# iospear310 register map
Registers are 32-bit, access not given, no defined reset value unless marked. A register's access mark holds for its fields unless they carry their own. Addresses are absolute; registers are grouped by the start of their names; [hi:lo] are bit positions; {n}, {i} and the like mark numbered series.

## MEMCTL
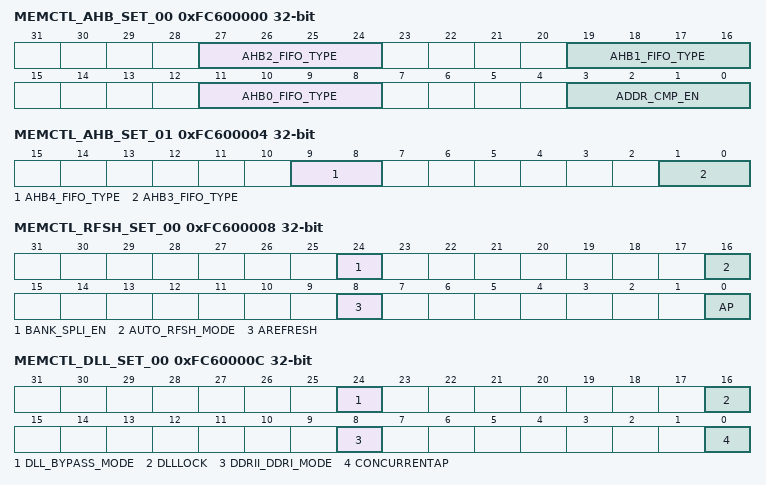
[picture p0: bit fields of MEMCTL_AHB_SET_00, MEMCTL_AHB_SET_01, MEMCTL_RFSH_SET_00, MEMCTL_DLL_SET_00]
0xFC600000 MEMCTL_AHB_SET_00
  [27:24] AHB2_FIFO_TYPE, [19:16] AHB1_FIFO_TYPE, [11:8] AHB0_FIFO_TYPE, [3:0] ADDR_CMP_EN
0xFC600004 MEMCTL_AHB_SET_01
  [9:8] AHB4_FIFO_TYPE, [1:0] AHB3_FIFO_TYPE
0xFC600008 MEMCTL_RFSH_SET_00
  [24] BANK_SPLI_EN, [16] AUTO_RFSH_MODE, [8] AREFRESH, [0] AP
0xFC60000C MEMCTL_DLL_SET_00
  [24] DLL_BYPASS_MODE, [16] DLLLOCK, [8] DDRII_DDRI_MODE, [0] CONCURRENTAP
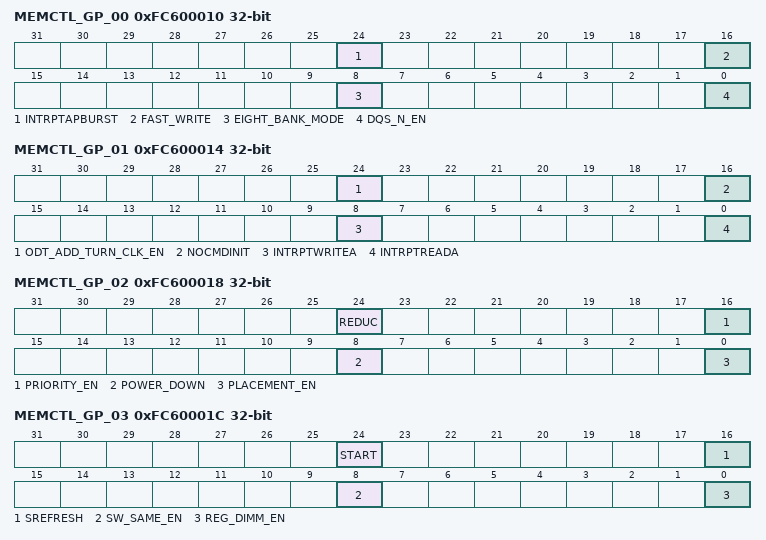
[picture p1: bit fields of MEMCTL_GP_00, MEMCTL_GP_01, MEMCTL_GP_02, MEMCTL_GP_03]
0xFC600010 MEMCTL_GP_00
  [24] INTRPTAPBURST, [16] FAST_WRITE, [8] EIGHT_BANK_MODE, [0] DQS_N_EN
0xFC600014 MEMCTL_GP_01
  [24] ODT_ADD_TURN_CLK_EN, [16] NOCMDINIT, [8] INTRPTWRITEA, [0] INTRPTREADA
0xFC600018 MEMCTL_GP_02
  [24] REDUC, [16] PRIORITY_EN, [8] POWER_DOWN, [0] PLACEMENT_EN
0xFC60001C MEMCTL_GP_03
  [24] START, [16] SREFRESH, [8] SW_SAME_EN, [0] REG_DIMM_EN
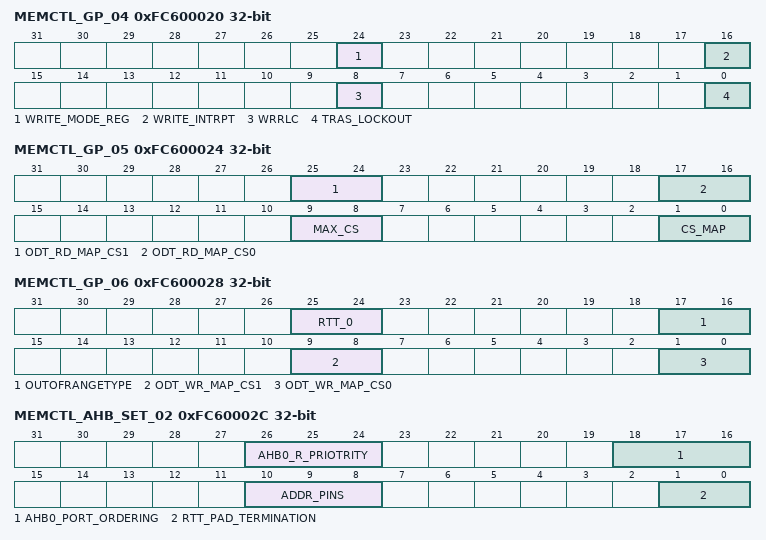
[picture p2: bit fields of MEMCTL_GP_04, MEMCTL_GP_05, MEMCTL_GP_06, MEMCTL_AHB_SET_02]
0xFC600020 MEMCTL_GP_04
  [24] WRITE_MODE_REG, [16] WRITE_INTRPT, [8] WRRLC, [0] TRAS_LOCKOUT
0xFC600024 MEMCTL_GP_05
  [25:24] ODT_RD_MAP_CS1, [17:16] ODT_RD_MAP_CS0, [9:8] MAX_CS, [1:0] CS_MAP
0xFC600028 MEMCTL_GP_06
  [25:24] RTT_0, [17:16] OUTOFRANGETYPE, [9:8] ODT_WR_MAP_CS1, [1:0] ODT_WR_MAP_CS0
0xFC60002C MEMCTL_AHB_SET_02
  [26:24] AHB0_R_PRIOTRITY, [18:16] AHB0_PORT_ORDERING, [10:8] ADDR_PINS, [1:0] RTT_PAD_TERMINATION
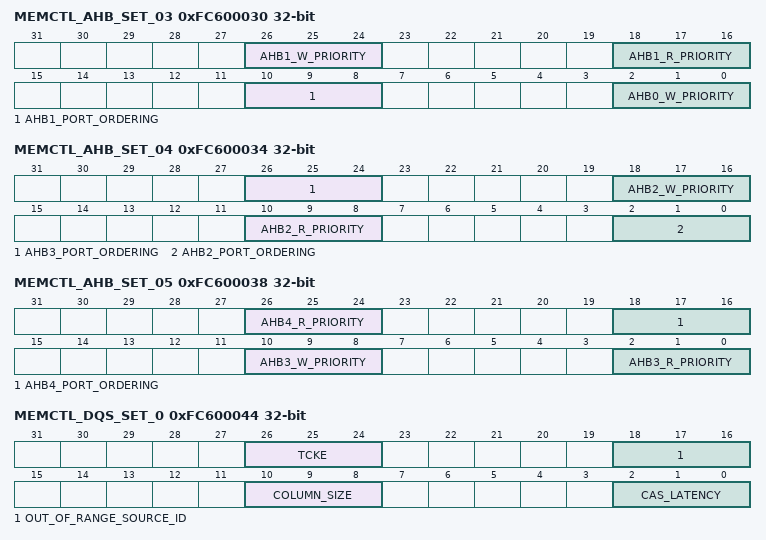
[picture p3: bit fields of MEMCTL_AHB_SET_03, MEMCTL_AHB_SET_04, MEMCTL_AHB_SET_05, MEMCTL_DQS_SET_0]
0xFC600030 MEMCTL_AHB_SET_03
  [26:24] AHB1_W_PRIORITY, [18:16] AHB1_R_PRIORITY, [10:8] AHB1_PORT_ORDERING, [2:0] AHB0_W_PRIORITY
0xFC600034 MEMCTL_AHB_SET_04
  [26:24] AHB3_PORT_ORDERING, [18:16] AHB2_W_PRIORITY, [10:8] AHB2_R_PRIORITY, [2:0] AHB2_PORT_ORDERING
0xFC600038 MEMCTL_AHB_SET_05
  [26:24] AHB4_R_PRIORITY, [18:16] AHB4_PORT_ORDERING, [10:8] AHB3_W_PRIORITY, [2:0] AHB3_R_PRIORITY
0xFC60003C MEMCTL_AHB_SET_06
  [2:0] AHB4_W_PRIORITY
0xFC600044 MEMCTL_DQS_SET_0
  [26:24] TCKE, [18:16] OUT_OF_RANGE_SOURCE_ID, [10:8] COLUMN_SIZE, [2:0] CAS_LATENCY
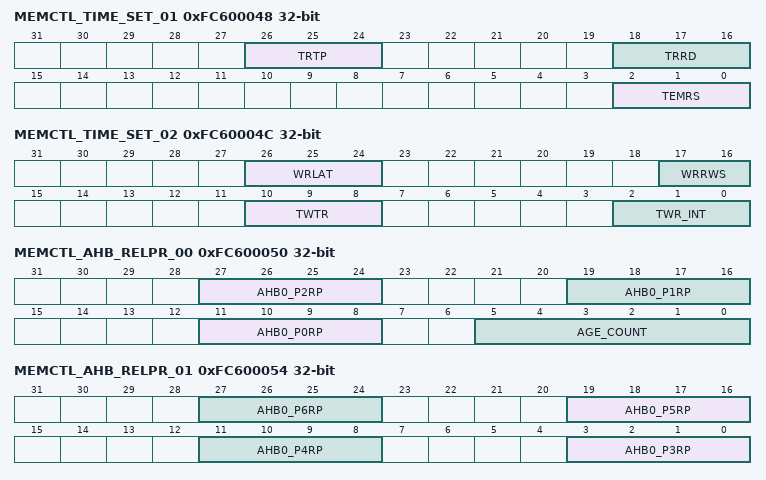
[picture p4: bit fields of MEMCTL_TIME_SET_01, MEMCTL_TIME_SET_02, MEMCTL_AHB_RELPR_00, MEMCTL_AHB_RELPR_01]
0xFC600048 MEMCTL_TIME_SET_01
  [26:24] TRTP, [18:16] TRRD, [2:0] TEMRS
0xFC60004C MEMCTL_TIME_SET_02
  [26:24] WRLAT, [17:16] WRRWS, [10:8] TWTR, [2:0] TWR_INT
0xFC600050 MEMCTL_AHB_RELPR_00
  [27:24] AHB0_P2RP, [19:16] AHB0_P1RP, [11:8] AHB0_P0RP, [5:0] AGE_COUNT
0xFC600054 MEMCTL_AHB_RELPR_01
  [8n-21:8n-24] AHB0_P{n}RP (n=3..6)
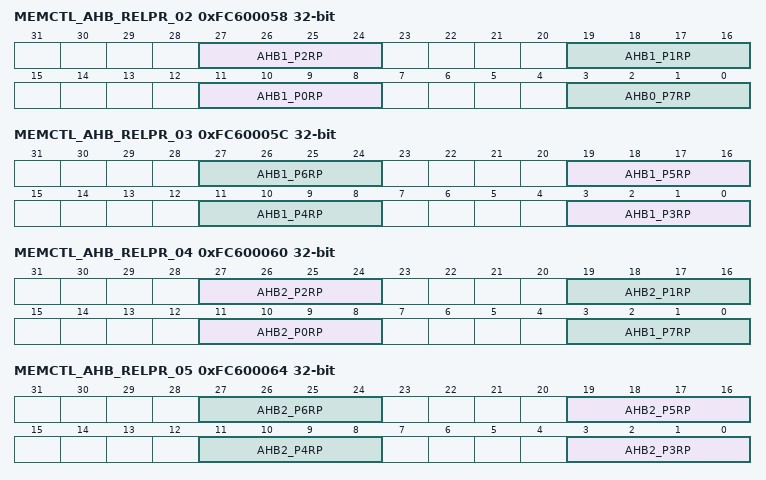
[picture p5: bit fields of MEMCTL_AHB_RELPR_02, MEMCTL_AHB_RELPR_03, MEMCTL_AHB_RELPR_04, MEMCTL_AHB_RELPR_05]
0xFC600058 MEMCTL_AHB_RELPR_02
  [27:24] AHB1_P2RP, [19:16] AHB1_P1RP, [11:8] AHB1_P0RP, [3:0] AHB0_P7RP
0xFC60005C MEMCTL_AHB_RELPR_03
  [8n-21:8n-24] AHB1_P{n}RP (n=3..6)
0xFC600060 MEMCTL_AHB_RELPR_04
  [27:24] AHB2_P2RP, [19:16] AHB2_P1RP, [11:8] AHB2_P0RP, [3:0] AHB1_P7RP
0xFC600064 MEMCTL_AHB_RELPR_05
  [8n-21:8n-24] AHB2_P{n}RP (n=3..6)
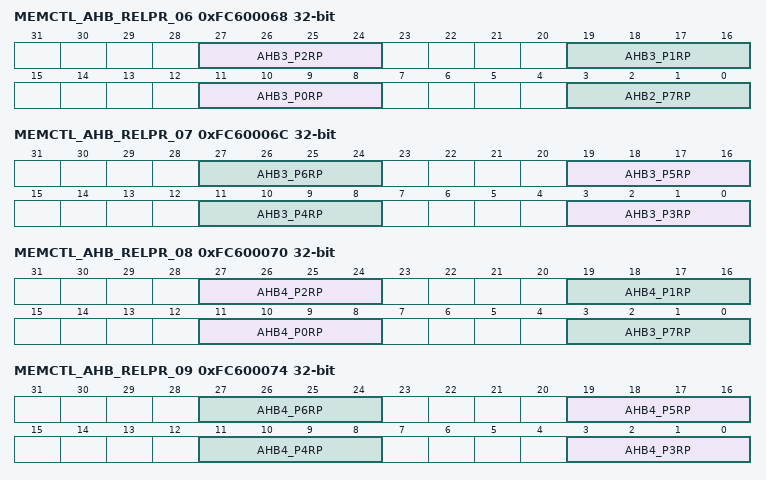
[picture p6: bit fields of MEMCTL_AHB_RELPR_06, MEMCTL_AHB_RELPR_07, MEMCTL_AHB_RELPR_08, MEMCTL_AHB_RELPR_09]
0xFC600068 MEMCTL_AHB_RELPR_06
  [27:24] AHB3_P2RP, [19:16] AHB3_P1RP, [11:8] AHB3_P0RP, [3:0] AHB2_P7RP
0xFC60006C MEMCTL_AHB_RELPR_07
  [8n-21:8n-24] AHB3_P{n}RP (n=3..6)
0xFC600070 MEMCTL_AHB_RELPR_08
  [27:24] AHB4_P2RP, [19:16] AHB4_P1RP, [11:8] AHB4_P0RP, [3:0] AHB3_P7RP
0xFC600074 MEMCTL_AHB_RELPR_09
  [8n-21:8n-24] AHB4_P{n}RP (n=3..6)
0xFC600078 MEMCTL_AHB_RELPR_10
  [3:0] AHB4_P7RP
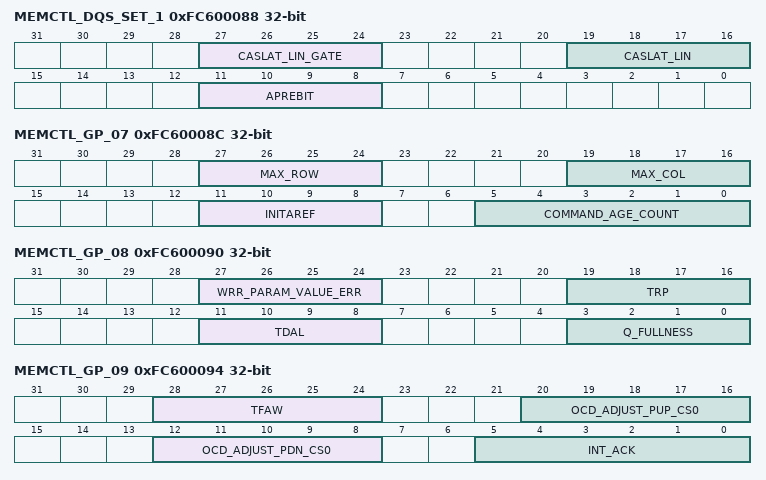
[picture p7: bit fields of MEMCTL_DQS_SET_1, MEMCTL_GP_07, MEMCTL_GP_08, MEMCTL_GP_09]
0xFC600088 MEMCTL_DQS_SET_1
  [27:24] CASLAT_LIN_GATE, [19:16] CASLAT_LIN, [11:8] APREBIT
0xFC60008C MEMCTL_GP_07
  [27:24] MAX_ROW, [19:16] MAX_COL, [11:8] INITAREF, [5:0] COMMAND_AGE_COUNT
0xFC600090 MEMCTL_GP_08
  [27:24] WRR_PARAM_VALUE_ERR, [19:16] TRP, [11:8] TDAL, [3:0] Q_FULLNESS
0xFC600094 MEMCTL_GP_09
  [28:24] TFAW, [20:16] OCD_ADJUST_PUP_CS0, [12:8] OCD_ADJUST_PDN_CS0, [5:0] INT_ACK
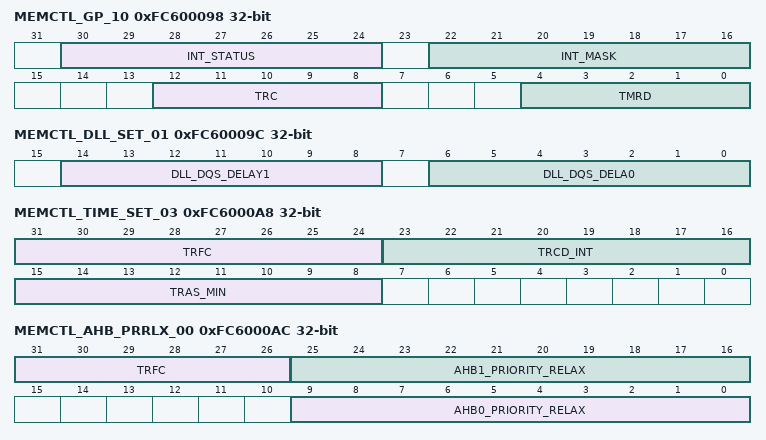
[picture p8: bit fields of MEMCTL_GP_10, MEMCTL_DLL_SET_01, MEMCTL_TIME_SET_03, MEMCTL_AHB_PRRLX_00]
0xFC600098 MEMCTL_GP_10
  [30:24] INT_STATUS, [22:16] INT_MASK, [12:8] TRC, [4:0] TMRD
0xFC60009C MEMCTL_DLL_SET_01
  [14:8] DLL_DQS_DELAY1, [6:0] DLL_DQS_DELA0
0xFC6000A0 MEMCTL_DQS_OUT_SHIFT
  [30:24] DQS_OUT_SHIFT
0xFC6000A4 MEMCTL_WR_DQS_SHIFT
  [22:16] WR_DQS_SHIFT
0xFC6000A8 MEMCTL_TIME_SET_03
  [31:24] TRFC, [23:16] TRCD_INT, [15:8] TRAS_MIN
0xFC6000AC MEMCTL_AHB_PRRLX_00
  [31:26] TRFC, [25:16] AHB1_PRIORITY_RELAX, [9:0] AHB0_PRIORITY_RELAX
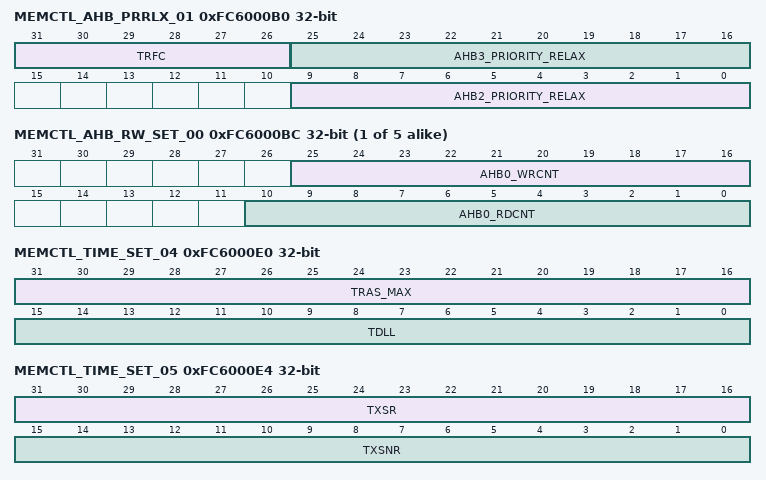
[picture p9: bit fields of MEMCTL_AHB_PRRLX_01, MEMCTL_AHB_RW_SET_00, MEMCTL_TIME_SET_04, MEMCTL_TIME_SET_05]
0xFC6000B0 MEMCTL_AHB_PRRLX_01
  [31:26] TRFC, [25:16] AHB3_PRIORITY_RELAX, [9:0] AHB2_PRIORITY_RELAX
0xFC6000B4 MEMCTL_AHB_PRRLX_02
  [9:0] AHB4_PRIORITY_RELAX
0xFC6000B8 MEMCTL_OUTRANGE_LGTH
  [25:16] OUT_OF_RANGE_LENGTH
{0xFC6000BC+4i} MEMCTL_AHB_RW_SET_{i:02} (i=0..4)
  [25:16] AHB{i}_WRCNT, [10:0] AHB{i}_RDCNT
0xFC6000D8 MEMCTL_TREF
  [13:0] TREF
0xFC6000DC MEMCTL_EMRS3_DATA
  [14:0] EMRS3_DATA
0xFC6000E0 MEMCTL_TIME_SET_04
  [31:16] TRAS_MAX, [15:0] TDLL
0xFC6000E4 MEMCTL_TIME_SET_05
  [31:16] TXSR, [15:0] TXSNR
0xFC6000E8 MEMCTL_VERSION
  [15:0] VERSION
0xFC6000EC MEMCTL_TINIT
  [23:0] TINIT
0xFC6000F0 MEMCTL_OUTRANGE_ADDR_01
0xFC6000F4 MEMCTL_OUTRANGE_ADDR_02
  [1:0] OUT_OF_RANGE_ADDR
0xFC600104 MEMCTL_DLL_DQS_DELAY_BYPASS_0
  [25:16] DLL_DQS_DELAY_BYPASS_0
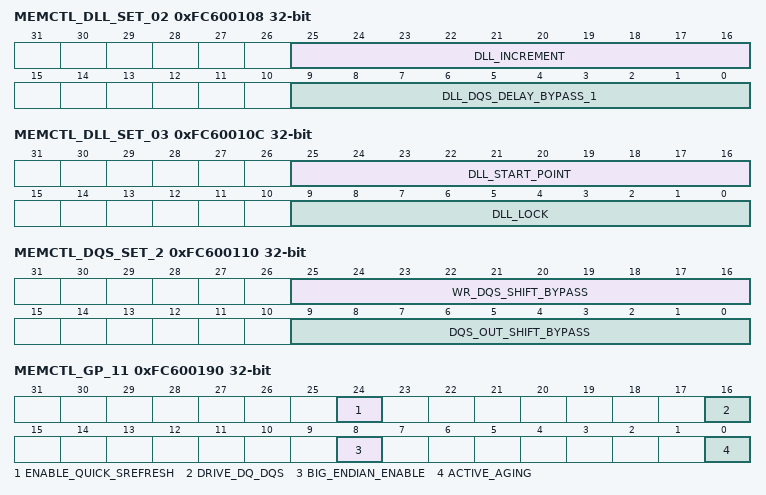
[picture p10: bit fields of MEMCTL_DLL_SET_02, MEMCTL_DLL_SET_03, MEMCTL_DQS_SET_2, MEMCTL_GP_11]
0xFC600108 MEMCTL_DLL_SET_02
  [25:16] DLL_INCREMENT, [9:0] DLL_DQS_DELAY_BYPASS_1
0xFC60010C MEMCTL_DLL_SET_03
  [25:16] DLL_START_POINT, [9:0] DLL_LOCK
0xFC600110 MEMCTL_DQS_SET_2
  [25:16] WR_DQS_SHIFT_BYPASS, [9:0] DQS_OUT_SHIFT_BYPASS
0xFC600188 MEMCTL_USER_DEF_REG_0
0xFC60018C MEMCTL_USER_DEF_REG_1
0xFC600190 MEMCTL_GP_11
  [24] ENABLE_QUICK_SREFRESH, [16] DRIVE_DQ_DQS, [8] BIG_ENDIAN_ENABLE, [0] ACTIVE_AGING
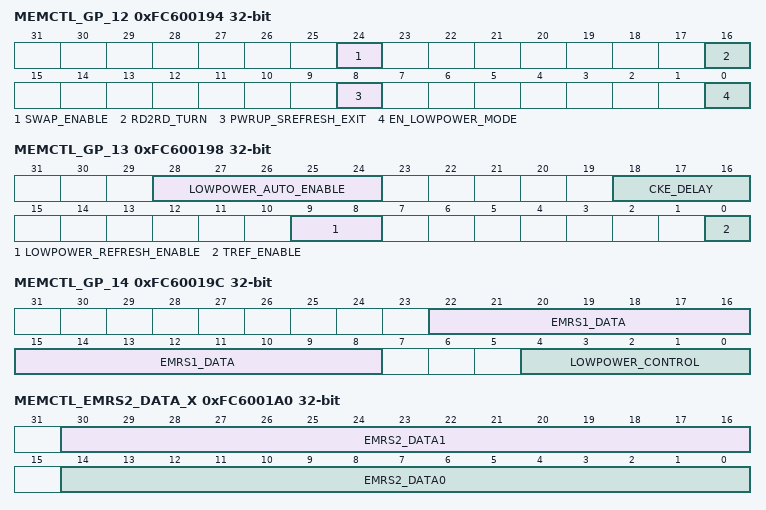
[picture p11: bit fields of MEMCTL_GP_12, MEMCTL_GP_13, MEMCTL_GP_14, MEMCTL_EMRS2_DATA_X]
0xFC600194 MEMCTL_GP_12
  [24] SWAP_ENABLE, [16] RD2RD_TURN, [8] PWRUP_SREFRESH_EXIT, [0] EN_LOWPOWER_MODE
0xFC600198 MEMCTL_GP_13
  [28:24] LOWPOWER_AUTO_ENABLE, [18:16] CKE_DELAY, [9:8] LOWPOWER_REFRESH_ENABLE, [0] TREF_ENABLE
0xFC60019C MEMCTL_GP_14
  [22:8] EMRS1_DATA, [4:0] LOWPOWER_CONTROL
0xFC6001A0 MEMCTL_EMRS2_DATA_X
  [30:16] EMRS2_DATA1, [14:0] EMRS2_DATA0
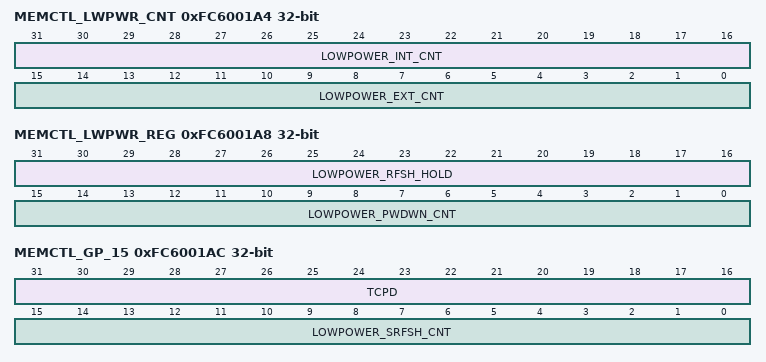
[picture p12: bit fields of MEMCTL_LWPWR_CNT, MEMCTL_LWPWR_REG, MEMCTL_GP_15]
0xFC6001A4 MEMCTL_LWPWR_CNT
  [31:16] LOWPOWER_INT_CNT, [15:0] LOWPOWER_EXT_CNT
0xFC6001A8 MEMCTL_LWPWR_REG
  [31:16] LOWPOWER_RFSH_HOLD, [15:0] LOWPOWER_PWDWN_CNT
0xFC6001AC MEMCTL_GP_15
  [31:16] TCPD, [15:0] LOWPOWER_SRFSH_CNT
0xFC6001B0 MEMCTL_TPDEX
  [15:0] TPDEX
